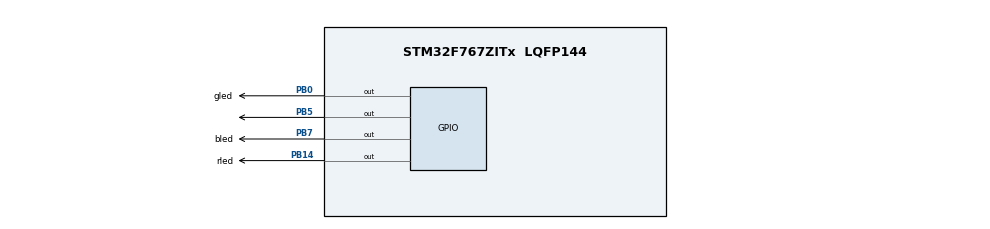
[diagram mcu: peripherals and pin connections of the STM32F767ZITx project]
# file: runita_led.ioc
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Mcu.Family=STM32F7
Mcu.Name=STM32F767ZITx
Mcu.Package=LQFP144
NVIC.PriorityGroup=NVIC_PRIORITYGROUP_4
PB0.GPIO_Label=gled
PB0.Signal=GPIO_Output
PB14.GPIO_Label=rled
PB14.Signal=GPIO_Output
PB5.Signal=GPIO_Output
PB7.GPIO_Label=bled
PB7.Signal=GPIO_Output
ProjectManager.HeapSize=0x200
ProjectManager.StackSize=0x400
ProjectManager.TargetToolchain=STM32CubeIDE
RCC.HSE_VALUE=25000000
RCC.HSI_VALUE=16000000
RCC.LSE_VALUE=32768
RCC.USBFreq_Value=96000000
RCC.VCOOutputFreq_Value=192000000
board=custom

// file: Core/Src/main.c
/* USER CODE BEGIN Header */
/**
  ******************************************************************************
  * @file           : main.c
  * @brief          : Main program body
  ******************************************************************************
  * @attention
  *
  * <h2><center>&copy; Copyright (c) 2023 STMicroelectronics.
  * All rights reserved.</center></h2>
  *
  * This software component is licensed by ST under BSD 3-Clause license,
  * the "License"; You may not use this file except in compliance with the
  * License. You may obtain a copy of the License at:
  *                        opensource.org/licenses/BSD-3-Clause
  *
  ******************************************************************************
  */
/* USER CODE END Header */
#include "main.h"

void SystemClock_Config(void);
static void MX_GPIO_Init(void);

int main(void)
{

  /* MCU Configuration--------------------------------------------------------*/

  /* Reset of all peripherals, Initializes the Flash interface and the Systick. */
  HAL_Init();

  /* Configure the system clock */
  SystemClock_Config();

  /* Initialize all configured peripherals */
  MX_GPIO_Init();

  /* Infinite loop */
  /* USER CODE BEGIN WHILE */
  while (1)
  {
	  HAL_GPIO_TogglePin(rled_GPIO_Port, rled_Pin);
	  HAL_GPIO_TogglePin(gled_GPIO_Port, gled_Pin);
	  HAL_GPIO_TogglePin(bled_GPIO_Port, bled_Pin);
	  HAL_Delay(500);

    /* USER CODE END WHILE */

  }
}

void SystemClock_Config(void)
{
  RCC_OscInitTypeDef RCC_OscInitStruct = {0};
  RCC_ClkInitTypeDef RCC_ClkInitStruct = {0};

  /** Configure the main internal regulator output voltage
  */
  __HAL_RCC_PWR_CLK_ENABLE();
  __HAL_PWR_VOLTAGESCALING_CONFIG(PWR_REGULATOR_VOLTAGE_SCALE3);
  /** Initializes the RCC Oscillators according to the specified parameters
  * in the RCC_OscInitTypeDef structure.
  */
  RCC_OscInitStruct.OscillatorType = RCC_OSCILLATORTYPE_HSI;
  RCC_OscInitStruct.HSIState = RCC_HSI_ON;
  RCC_OscInitStruct.HSICalibrationValue = RCC_HSICALIBRATION_DEFAULT;
  RCC_OscInitStruct.PLL.PLLState = RCC_PLL_NONE;
  if (HAL_RCC_OscConfig(&RCC_OscInitStruct) != HAL_OK)
  {
    Error_Handler();
  }
  /** Initializes the CPU, AHB and APB buses clocks
  */
  RCC_ClkInitStruct.ClockType = RCC_CLOCKTYPE_HCLK|RCC_CLOCKTYPE_SYSCLK
                              |RCC_CLOCKTYPE_PCLK1|RCC_CLOCKTYPE_PCLK2;
  RCC_ClkInitStruct.SYSCLKSource = RCC_SYSCLKSOURCE_HSI;
  RCC_ClkInitStruct.AHBCLKDivider = RCC_SYSCLK_DIV1;
  RCC_ClkInitStruct.APB1CLKDivider = RCC_HCLK_DIV1;
  RCC_ClkInitStruct.APB2CLKDivider = RCC_HCLK_DIV1;

  if (HAL_RCC_ClockConfig(&RCC_ClkInitStruct, FLASH_LATENCY_0) != HAL_OK)
  {
    Error_Handler();
  }
}

static void MX_GPIO_Init(void)
{
  GPIO_InitTypeDef GPIO_InitStruct = {0};

  /* GPIO Ports Clock Enable */
  __HAL_RCC_GPIOB_CLK_ENABLE();

  /*Configure GPIO pin Output Level */
  HAL_GPIO_WritePin(GPIOB, gled_Pin|rled_Pin|GPIO_PIN_5|bled_Pin, GPIO_PIN_RESET);

  /*Configure GPIO pins : gled_Pin rled_Pin PB5 bled_Pin */
  GPIO_InitStruct.Pin = gled_Pin|rled_Pin|GPIO_PIN_5|bled_Pin;
  GPIO_InitStruct.Mode = GPIO_MODE_OUTPUT_PP;
  GPIO_InitStruct.Pull = GPIO_NOPULL;
  GPIO_InitStruct.Speed = GPIO_SPEED_FREQ_LOW;
  HAL_GPIO_Init(GPIOB, &GPIO_InitStruct);

}

void Error_Handler(void)
{
  __disable_irq();
  while (1)
  {
  }
}

/************************ (C) COPYRIGHT STMicroelectronics *****END OF FILE****/
